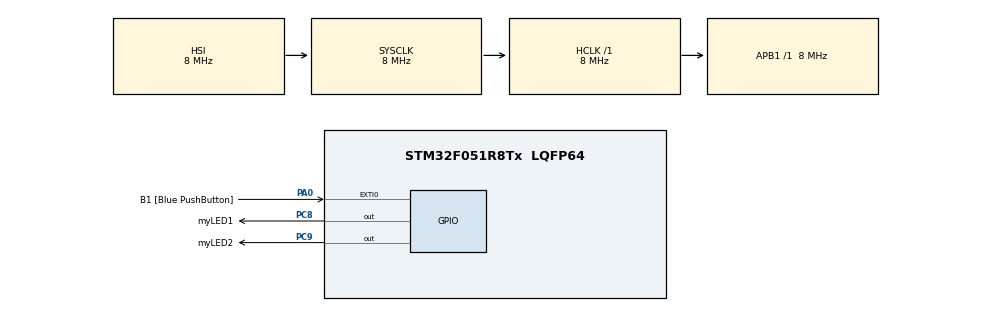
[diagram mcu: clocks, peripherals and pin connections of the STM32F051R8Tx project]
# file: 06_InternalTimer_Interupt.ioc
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Mcu.Family=STM32F0
Mcu.Name=STM32F051R8Tx
Mcu.Package=LQFP64
NVIC.TIM2_IRQn=true\:0\:0\:false\:false\:true\:true\:true
PA0.GPIO_Label=B1 [Blue PushButton]
PA0.GPIO_ModeDefaultEXTI=GPIO_MODE_EVT_RISING
PA0.Signal=GPXTI0
PA13.GPIO_Label=SWDIO
PA13.Signal=SYS_SWDIO
PA14.GPIO_Label=SWCLK
PA14.Signal=SYS_SWCLK
PC8.GPIO_Label=myLED1
PC8.Signal=GPIO_Output
PC9.GPIO_Label=myLED2
PC9.Signal=GPIO_Output
ProjectManager.HeapSize=0x200
ProjectManager.StackSize=0x400
ProjectManager.TargetToolchain=STM32CubeIDE
RCC.AHBFreq_Value=8000000
RCC.APB1Freq_Value=8000000
RCC.APB1TimFreq_Value=8000000
RCC.HCLKFreq_Value=8000000
RCC.PLLMUL=RCC_PLL_MUL12
RCC.SYSCLKFreq_VALUE=8000000
TIM2.Period=1000
TIM2.Prescaler=3200
VP_TIM2_VS_ClockSourceINT.Mode=Internal
board=STM32F0DISCOVERY

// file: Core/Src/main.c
/* USER CODE BEGIN Header */
/**
  ******************************************************************************
  * @file           : main.c
  * @brief          : Main program body
  ******************************************************************************
  * @attention
  *
  * <h2><center>&copy; Copyright (c) 2023 STMicroelectronics.
  * All rights reserved.</center></h2>
  *
  * This software component is licensed by ST under BSD 3-Clause license,
  * the "License"; You may not use this file except in compliance with the
  * License. You may obtain a copy of the License at:
  *                        opensource.org/licenses/BSD-3-Clause
  *
  ******************************************************************************
  */
/* USER CODE END Header */
#include "main.h"

TIM_HandleTypeDef htim2;

void SystemClock_Config(void);
static void MX_GPIO_Init(void);
static void MX_TIM2_Init(void);

int main(void)
{

  /* MCU Configuration--------------------------------------------------------*/

  /* Reset of all peripherals, Initializes the Flash interface and the Systick. */
  HAL_Init();

  /* Configure the system clock */
  SystemClock_Config();

  /* Initialize all configured peripherals */
  MX_GPIO_Init();
  MX_TIM2_Init();
  /* USER CODE BEGIN 2 */
  HAL_TIM_Base_Start_IT(&htim2);  ///intializing timmer, this will start the timer and as timer starts,it count for 1000,after 1000 it will generate interupt.
  /* USER CODE END 2 */

  /* Infinite loop */
  while (1)
  {
	  HAL_GPIO_TogglePin(myLED1_GPIO_Port, myLED1_Pin);
	  HAL_Delay(1000);
  }
}

void SystemClock_Config(void)
{
  RCC_OscInitTypeDef RCC_OscInitStruct = {0};
  RCC_ClkInitTypeDef RCC_ClkInitStruct = {0};

  /** Initializes the RCC Oscillators according to the specified parameters
  * in the RCC_OscInitTypeDef structure.
  */
  RCC_OscInitStruct.OscillatorType = RCC_OSCILLATORTYPE_HSI;
  RCC_OscInitStruct.HSIState = RCC_HSI_ON;
  RCC_OscInitStruct.HSICalibrationValue = RCC_HSICALIBRATION_DEFAULT;
  RCC_OscInitStruct.PLL.PLLState = RCC_PLL_NONE;
  if (HAL_RCC_OscConfig(&RCC_OscInitStruct) != HAL_OK)
  {
    Error_Handler();
  }
  /** Initializes the CPU, AHB and APB buses clocks
  */
  RCC_ClkInitStruct.ClockType = RCC_CLOCKTYPE_HCLK|RCC_CLOCKTYPE_SYSCLK
                              |RCC_CLOCKTYPE_PCLK1;
  RCC_ClkInitStruct.SYSCLKSource = RCC_SYSCLKSOURCE_HSI;
  RCC_ClkInitStruct.AHBCLKDivider = RCC_SYSCLK_DIV1;
  RCC_ClkInitStruct.APB1CLKDivider = RCC_HCLK_DIV1;

  if (HAL_RCC_ClockConfig(&RCC_ClkInitStruct, FLASH_LATENCY_0) != HAL_OK)
  {
    Error_Handler();
  }
}

static void MX_TIM2_Init(void)
{

  TIM_ClockConfigTypeDef sClockSourceConfig = {0};
  TIM_MasterConfigTypeDef sMasterConfig = {0};

  htim2.Instance = TIM2;
  htim2.Init.Prescaler = 8000;  //internal clk is 8MHz so prescale by 8000 to generate 1 msec.
  htim2.Init.CounterMode = TIM_COUNTERMODE_UP;
  htim2.Init.Period = 1000; //counting 1000 milisecnds and then genreating interupt.
  htim2.Init.ClockDivision = TIM_CLOCKDIVISION_DIV1;
  htim2.Init.AutoReloadPreload = TIM_AUTORELOAD_PRELOAD_DISABLE;
  if (HAL_TIM_Base_Init(&htim2) != HAL_OK)
  {
    Error_Handler();
  }
  sClockSourceConfig.ClockSource = TIM_CLOCKSOURCE_INTERNAL;
  if (HAL_TIM_ConfigClockSource(&htim2, &sClockSourceConfig) != HAL_OK)
  {
    Error_Handler();
  }
  sMasterConfig.MasterOutputTrigger = TIM_TRGO_RESET;
  sMasterConfig.MasterSlaveMode = TIM_MASTERSLAVEMODE_DISABLE;
  if (HAL_TIMEx_MasterConfigSynchronization(&htim2, &sMasterConfig) != HAL_OK)
  {
    Error_Handler();
  }

}

static void MX_GPIO_Init(void)
{
  GPIO_InitTypeDef GPIO_InitStruct = {0};

  /* GPIO Ports Clock Enable */
  __HAL_RCC_GPIOA_CLK_ENABLE();
  __HAL_RCC_GPIOC_CLK_ENABLE();

  /*Configure GPIO pin Output Level */
  HAL_GPIO_WritePin(GPIOC, myLED1_Pin|myLED2_Pin, GPIO_PIN_RESET);

  /*Configure GPIO pin : B1_Pin */
  GPIO_InitStruct.Pin = B1_Pin;
  GPIO_InitStruct.Mode = GPIO_MODE_EVT_RISING;
  GPIO_InitStruct.Pull = GPIO_NOPULL;
  HAL_GPIO_Init(B1_GPIO_Port, &GPIO_InitStruct);

  /*Configure GPIO pins : myLED1_Pin myLED2_Pin */
  GPIO_InitStruct.Pin = myLED1_Pin|myLED2_Pin;
  GPIO_InitStruct.Mode = GPIO_MODE_OUTPUT_PP;
  GPIO_InitStruct.Pull = GPIO_NOPULL;
  GPIO_InitStruct.Speed = GPIO_SPEED_FREQ_LOW;
  HAL_GPIO_Init(GPIOC, &GPIO_InitStruct);

}

/* USER CODE BEGIN 4 */
void HAL_TIM_PeriodElapsedCallback(TIM_HandleTypeDef *htim)

{
	if(htim->Instance==TIM2)
	{
		HAL_GPIO_TogglePin(myLED2_GPIO_Port, myLED2_Pin);

	}

}
/* USER CODE END 4 */

void Error_Handler(void)
{
  __disable_irq();
  while (1)
  {
  }
}

/************************ (C) COPYRIGHT STMicroelectronics *****END OF FILE****/
